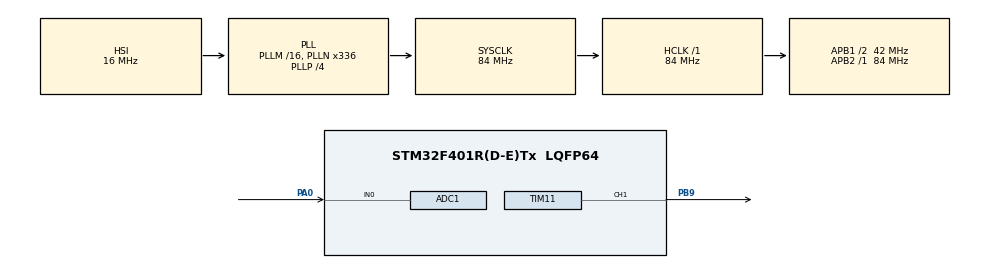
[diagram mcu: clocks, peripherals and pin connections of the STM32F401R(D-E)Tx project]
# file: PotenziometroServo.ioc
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ADC1.Channel-0\#ChannelRegularConversion=ADC_CHANNEL_0
ADC1.NbrOfConversionFlag=1
ADC1.Rank-0\#ChannelRegularConversion=1
ADC1.SamplingTime-0\#ChannelRegularConversion=ADC_SAMPLETIME_3CYCLES
ADC1.master=1
Mcu.Family=STM32F4
Mcu.Name=STM32F401R(D-E)Tx
Mcu.Package=LQFP64
NVIC.ADC_IRQn=true\:0\:0\:false\:false\:true\:true\:true\:true
NVIC.PriorityGroup=NVIC_PRIORITYGROUP_0
PA0-WKUP.Signal=ADCx_IN0
PB9.Signal=S_TIM11_CH1
ProjectManager.HeapSize=0x200
ProjectManager.StackSize=0x400
ProjectManager.TargetToolchain=STM32CubeIDE
RCC.48MHZClocksFreq_Value=48000000
RCC.AHBFreq_Value=84000000
RCC.APB1CLKDivider=RCC_HCLK_DIV2
RCC.APB1Freq_Value=42000000
RCC.APB1TimFreq_Value=84000000
RCC.APB2Freq_Value=84000000
RCC.APB2TimFreq_Value=84000000
RCC.CortexFreq_Value=84000000
RCC.HCLKFreq_Value=84000000
RCC.HSE_VALUE=8000000
RCC.HSI_VALUE=16000000
RCC.LSE_VALUE=32768
RCC.PLLN=336
RCC.PLLP=RCC_PLLP_DIV4
RCC.PLLQ=7
RCC.SYSCLKFreq_VALUE=84000000
RCC.SYSCLKSource=RCC_SYSCLKSOURCE_PLLCLK
RCC.VCOOutputFreq_Value=336000000
SH.ADCx_IN0.0=ADC1_IN0,IN0
SH.S_TIM11_CH1.0=TIM11_CH1,PWM Generation1 CH1
TIM11.Channel=TIM_CHANNEL_1
TIM11.Period=64614
TIM11.Prescaler=25
VP_TIM11_VS_ClockSourceINT.Mode=Enable_Timer
board=NUCLEO-F401RE

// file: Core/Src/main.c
/* USER CODE BEGIN Header */
/**
  ******************************************************************************
  * @file           : main.c
  * @brief          : Main program body
  ******************************************************************************
  * @attention
  *
  * Copyright (c) 2023 STMicroelectronics.
  * All rights reserved.
  *
  * This software is licensed under terms that can be found in the LICENSE file
  * in the root directory of this software component.
  * If no LICENSE file comes with this software, it is provided AS-IS.
  *
  ******************************************************************************
  */
/* USER CODE END Header */
#include "main.h"
#include "adc.h"
#include "tim.h"
#include "gpio.h"

void SystemClock_Config(void);

/* USER CODE BEGIN 0 */
uint16_t iteration = 0;

static void set_duty_cycle(TIM_HandleTypeDef* const htim, uint32_t channel, float duty_cycle) {
	if (duty_cycle > 100) duty_cycle = 100;
	if (duty_cycle < 0) duty_cycle = 0;

	float pw_resolution = (((float)(*htim).Init.Period + 1.0f) / 100.0f);

	uint16_t pw_desired = pw_resolution * duty_cycle;
	__HAL_TIM_SET_COMPARE(htim, channel, pw_desired);
}

/* USER CODE END 0 */

int main(void)
{

  /* MCU Configuration--------------------------------------------------------*/

  /* Reset of all peripherals, Initializes the Flash interface and the Systick. */
  HAL_Init();

  /* Configure the system clock */
  SystemClock_Config();

  /* Initialize all configured peripherals */
  MX_GPIO_Init();
  MX_ADC1_Init();
  MX_TIM11_Init();
  /* USER CODE BEGIN 2 */
  HAL_TIM_PWM_Start(&htim11,TIM_CHANNEL_1);
  uint16_t min_servo = 2500;
  uint16_t max_servo = 7700;
  iteration = min_servo;
  /* USER CODE END 2 */

  /* Infinite loop */
  while (1)
  {

    /* USER CODE BEGIN 3 */
	  TIM11->CCR1 = min_servo;
	  HAL_Delay(1000);
	  TIM11->CCR1 = (max_servo+min_servo)/2;
	  HAL_Delay(1000);
	  TIM11->CCR1 = max_servo;
	  HAL_Delay(1000);
  }
  /* USER CODE END 3 */
}

void SystemClock_Config(void)
{
  RCC_OscInitTypeDef RCC_OscInitStruct = {0};
  RCC_ClkInitTypeDef RCC_ClkInitStruct = {0};

  /** Configure the main internal regulator output voltage
  */
  __HAL_RCC_PWR_CLK_ENABLE();
  __HAL_PWR_VOLTAGESCALING_CONFIG(PWR_REGULATOR_VOLTAGE_SCALE2);

  /** Initializes the RCC Oscillators according to the specified parameters
  * in the RCC_OscInitTypeDef structure.
  */
  RCC_OscInitStruct.OscillatorType = RCC_OSCILLATORTYPE_HSI;
  RCC_OscInitStruct.HSIState = RCC_HSI_ON;
  RCC_OscInitStruct.HSICalibrationValue = RCC_HSICALIBRATION_DEFAULT;
  RCC_OscInitStruct.PLL.PLLState = RCC_PLL_ON;
  RCC_OscInitStruct.PLL.PLLSource = RCC_PLLSOURCE_HSI;
  RCC_OscInitStruct.PLL.PLLM = 16;
  RCC_OscInitStruct.PLL.PLLN = 336;
  RCC_OscInitStruct.PLL.PLLP = RCC_PLLP_DIV4;
  RCC_OscInitStruct.PLL.PLLQ = 7;
  if (HAL_RCC_OscConfig(&RCC_OscInitStruct) != HAL_OK)
  {
    Error_Handler();
  }

  /** Initializes the CPU, AHB and APB buses clocks
  */
  RCC_ClkInitStruct.ClockType = RCC_CLOCKTYPE_HCLK|RCC_CLOCKTYPE_SYSCLK
                              |RCC_CLOCKTYPE_PCLK1|RCC_CLOCKTYPE_PCLK2;
  RCC_ClkInitStruct.SYSCLKSource = RCC_SYSCLKSOURCE_PLLCLK;
  RCC_ClkInitStruct.AHBCLKDivider = RCC_SYSCLK_DIV1;
  RCC_ClkInitStruct.APB1CLKDivider = RCC_HCLK_DIV2;
  RCC_ClkInitStruct.APB2CLKDivider = RCC_HCLK_DIV1;

  if (HAL_RCC_ClockConfig(&RCC_ClkInitStruct, FLASH_LATENCY_2) != HAL_OK)
  {
    Error_Handler();
  }
}

void Error_Handler(void)
{
  __disable_irq();
  while (1)
  {
  }
}
